AUTOSAR XML (schema 4-3-0)
package /App_Secure
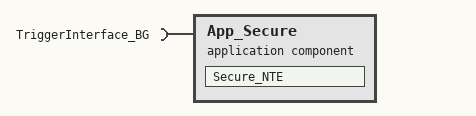
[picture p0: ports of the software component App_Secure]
  application sw component type App_Secure
    require port TriggerInterface_BG: required-interface=TriggerInterface_BG
    behavior InternalBehavior
      external trigger occurred event ETOE_Secure_NTE_TriggerInterface_BG_Trigger_BG: start-on-event=Secure_NTE, trigger=TriggerInterface_BG.Trigger_BG
      runnable Secure_NTE: symbol=Secure_NTE_Runnable
  trigger interface TriggerInterface_BG
    trigger Trigger_BG: sw-impl-policy=QUEUED
